# STM32WB05 register map
File version: 0.3
CPU: CM0+ r0p0, little endian, MPU, no FPU, 4 interrupt priority bits
Registers are 32-bit, read-write, reset 0x0 unless marked. A register's access mark holds for its fields unless they carry their own. Offsets are from the block's base; [hi:lo] are bit positions; {n}, {i} and the like mark numbered series.

## FLASH_CTRL — 4kb addressable space
Base 0x40001000
0x00 COMMAND
  [7:0] COMMAND — Macro commands for flash operations (may require DATA0...DATA3 to be set): - 0x11 : ERASE - 0x22 : MASSERASE - 0x33 : WRITE - 0x44 : MASSWRITE - 0x55 : MASSREAD - 0x66 : IFRERASE - 0x77 : IFRWRITE - 0x88 : IFRMASSWRITE - 0x99 : IFRMASSREAD - 0xAA : SLEEP - 0xBB : WAKEUP - 0xCC : BURSTWRITE - 0xDD : IFRBURSTWRITE - 0xEE : OTPWRITE - 0xFF : KEYWRITE
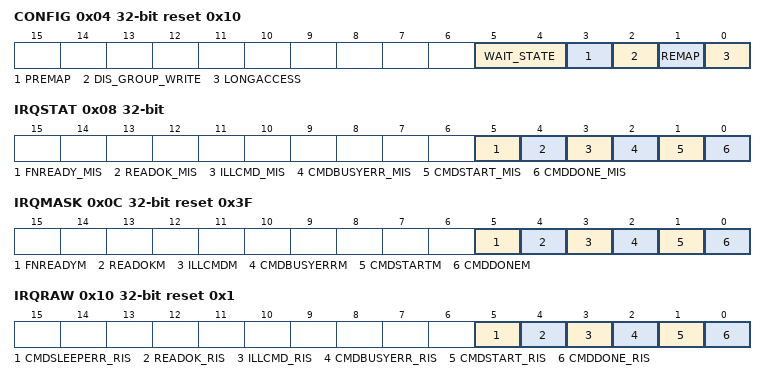
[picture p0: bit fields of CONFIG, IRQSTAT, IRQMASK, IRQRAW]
0x04 CONFIG reset 0x10
  [5:4] WAIT_STATE — Add latency to flash read opeations: - 00 : no latency - 01 : 1 clock cycle latency - 10 : 2 clock cycles latency - 11 : 3 clock cycles latency
  [3] PREMAP — CPU access routing (it can only be set; reset only allowed by POR/PAD reset) - 0 : IFR memory addressed - 1 : MAIN flash memory addressed
  [2] DIS_GROUP_WRITE — Burst write Control: - 0 : burst write allowed - 1 : burst write forbidden
  [1] REMAP — CPU access routing (it supersedes PREMAP configuration): - 0 : FLASH memory addressed - 1 : SRAM0 memory addressed
  [0] LONGACCESS — Additional wait-state for flash read access: - 0 : no latency added - 1 : 1 clock cycle latency added
0x08 IRQSTAT
  [5] FNREADY_MIS — (1: clear, 0: inactive) FNREADY_MIS flag
  [4] READOK_MIS — (1: clear, 0: inactive) READOK_MIS flag
  [3] ILLCMD_MIS — (1: clear, 0: inactive) ILLCMD_MIS flag
  [2] CMDBUSYERR_MIS — (1: clear, 0: inactive) CMDBUSYERR_MIS flag
  [1] CMDSTART_MIS — (1: clear, 0: inactive) CMDSTART_MIS flag
  [0] CMDDONE_MIS — (1: clear, 0: inactive) CMDDONE_MIS flag
0x0C IRQMASK reset 0x3F
  [5] FNREADYM — (1: mask, 0: inactive) FNREADY_MIS mask
  [4] READOKM — (1: mask, 0: inactive) READOK_MIS mask
  [3] ILLCMDM — (1: mask, 0: inactive) ILLCMD_MIS mask
  [2] CMDBUSYERRM — (1: mask, 0: inactive) CMDBUSYERR_MIS mask
  [1] CMDSTARTM — (1: mask, 0: inactive) CMDSTART_MIS mask
  [0] CMDDONEM — (1: mask, 0: inactive) CMDDONE_MIS mask
0x10 IRQRAW reset 0x1
  [5] CMDSLEEPERR_RIS — (1: active, 0: inactive) COMMAND issued while flash in sleep-mode (SLM=1)
  [4] READOK_RIS — (1: active, 0: inactive) READ COMMAND completed successfully
  [3] ILLCMD_RIS — (1: active, 0: inactive) Illegal command issued
  [2] CMDBUSYERR_RIS — (1: active, 0: inactive) COMMAND issued while flash busy
  [1] CMDSTART_RIS — (1: active, 0: inactive) COMMAND sequence started
  [0] CMDDONE_RIS — (1: active, 0: inactive) COMMAND sequence ended
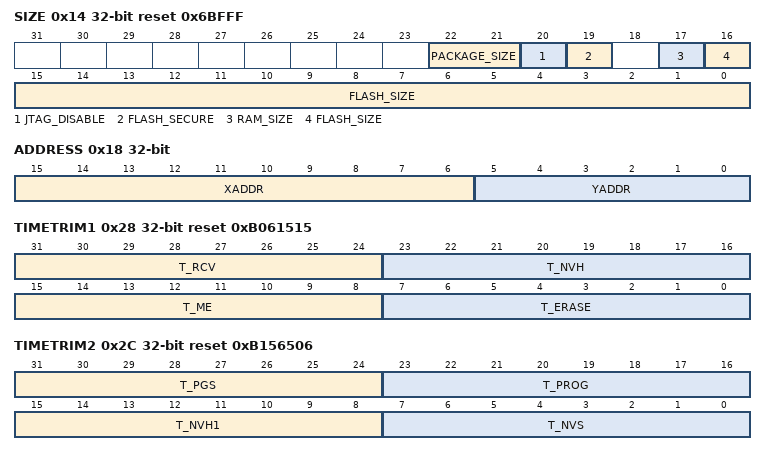
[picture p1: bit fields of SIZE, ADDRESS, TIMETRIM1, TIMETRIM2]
0x14 SIZE ro reset 0x6BFFF
  [22:21] PACKAGE_SIZE — Package selection: - 0- : CSP - 10 : 32pins - 11 : 48pins
  [20] JTAG_DISABLE — Flash+JTAG protection (0: no JTAG protection - see FLASH_SECURE, 1: Flash and JTAG protected)
  [19] FLASH_SECURE — Flash memory protection (0: no key present, 1: key present)
  [17] RAM_SIZE — RAM memory size selection: - 0 : 16kb - 1 : 32kb
  [16:0] FLASH_SIZE — Maximum valid address for flash memory: - 00 : 0x03FFF (64kb) - 01 : 0x07FFF (128kb) - 10 : 0x09FFF (160kb) - 11 : 0x0BFFF (192kb)
0x18 ADDRESS
  [15:6] XADDR — Flash row address offset to be used with some COMMAND
  [5:0] YADDR — Flash column address offset to be used with some COMMAND
0x1C UNLOCKM reset 0xFFFFFFFF
  [31:0] UNLOCKM — User flash memory protection 64-bit key MSW
0x20 UNLOCKL reset 0xFFFFFFFF
  [31:0] UNLOCKL — User flash memory protection 64-bit key LSW
0x24 LFSRVAL ro reset 0xFFFFFFFF
  [31:0] LFSRVAL — Flash read data CRC signature
0x28 TIMETRIM1 reset 0xB061515
  [31:24] T_RCV — Recovery time (us)
  [23:16] T_NVH — NVSTR hold time (us)
  [15:8] T_ME — Mass erase time (ms)
  [7:0] T_ERASE — Erase time (ms)
0x2C TIMETRIM2 reset 0xB156506
  [31:24] T_PGS — NVSTR to program set-up time (us)
  [23:16] T_PROG — Program time (us)
  [15:8] T_NVH1 — NVSTR hold time for mass erase (us)
  [7:0] T_NVS — NVSTR setup time (us)
0x30 TIMETRIM3 reset 0x11
  [7:0] T_WK — Wake-up time from sleep/power-down to standby (us)
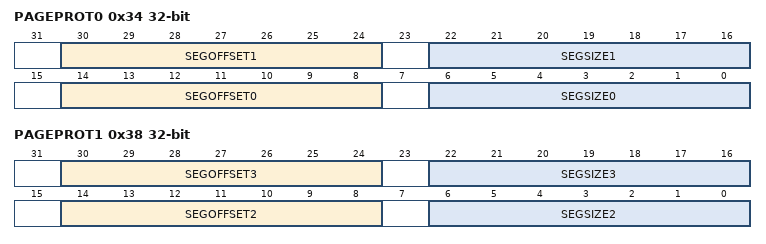
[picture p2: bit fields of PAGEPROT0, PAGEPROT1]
0x34 PAGEPROT0
  [30:24] SEGOFFSET1 — Second segment, 7-bit page protection offset (first page number in protected segment)
  [22:16] SEGSIZE1 — Second segment, 7-bit page protection size (number of pages to protect in segment, first page included)
  [14:8] SEGOFFSET0 — First segment, 7-bit page protection offset (first page number in protected segment)
  [6:0] SEGSIZE0 — First segment, 7-bit page protection size (number of pages to protect in segment, first page included)
0x38 PAGEPROT1
  [30:24] SEGOFFSET3 — Fourth segment, 7-bit page protection offset (first page number in protected segment)
  [22:16] SEGSIZE3 — Fourth segment, 7-bit page protection size (number of pages to protect in segment, first page included)
  [14:8] SEGOFFSET2 — Third segment, 7-bit page protection offset (first page number in protected segment)
  [6:0] SEGSIZE2 — Third segment, 7-bit page protection size (number of pages to protect in segment, first page included)
0x40 DATA0 reset 0xFFFFFFFF
  [31:0] DATA0 — Value to be used as DATA for any COMMAND of type WRITE and compare value for MASSREAD
{0x40+4i} DATA{i} reset 0xFFFFFFFF (i=1..3)
  [31:0] DATA{i} — Value to be used as DATA for any COMMAND of type WRITE
